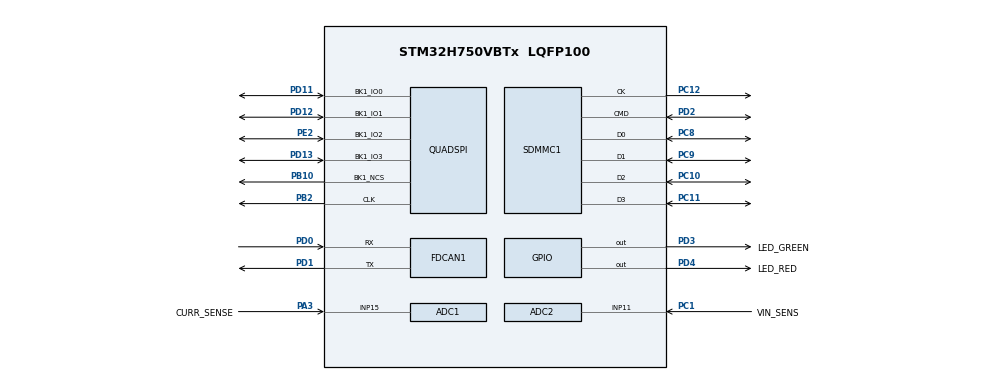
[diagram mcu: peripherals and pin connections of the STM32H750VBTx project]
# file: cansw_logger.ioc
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ADC1.Channel-0\#ChannelRegularConversion=ADC_CHANNEL_15
ADC1.ClockPrescaler=ADC_CLOCK_ASYNC_DIV64
ADC1.NbrOfConversionFlag=1
ADC1.OffsetNumber-0\#ChannelRegularConversion=ADC_OFFSET_NONE
ADC1.OffsetSignedSaturation-0\#ChannelRegularConversion=DISABLE
ADC1.Rank-0\#ChannelRegularConversion=1
ADC1.Resolution=ADC_RESOLUTION_12B
ADC1.SamplingTime-0\#ChannelRegularConversion=ADC_SAMPLETIME_1CYCLE_5
ADC1.master=1
ADC2.Channel-1\#ChannelRegularConversion=ADC_CHANNEL_11
ADC2.ClockPrescaler=ADC_CLOCK_ASYNC_DIV64
ADC2.NbrOfConversionFlag=1
ADC2.OffsetNumber-1\#ChannelRegularConversion=ADC_OFFSET_NONE
ADC2.OffsetSignedSaturation-1\#ChannelRegularConversion=DISABLE
ADC2.Rank-1\#ChannelRegularConversion=1
ADC2.Resolution=ADC_RESOLUTION_12B
ADC2.SamplingTime-1\#ChannelRegularConversion=ADC_SAMPLETIME_1CYCLE_5
CORTEX_M7.default_mode_Activation=1
FATFS.USE_DMA_CODE_SD=1
FDCAN1.CalculateBaudRateNominal=250000
FDCAN1.CalculateTimeBitNominal=4000
FDCAN1.CalculateTimeQuantumNominal=1333.3333333333333
FDCAN1.NominalPrescaler=64
FDCAN1.RxFifo0ElmtsNbr=64
FDCAN1.TxEventsNbr=32
FDCAN1.TxFifoQueueElmtsNbr=32
Mcu.Family=STM32H7
Mcu.Name=STM32H750VBTx
Mcu.Package=LQFP100
NVIC.FDCAN1_IT0_IRQn=true\:0\:0\:false\:false\:true\:true\:true\:true
NVIC.FDCAN1_IT1_IRQn=true\:0\:0\:false\:false\:true\:true\:true\:true
NVIC.FDCAN_CAL_IRQn=true\:0\:0\:false\:false\:true\:true\:true\:true
NVIC.PriorityGroup=NVIC_PRIORITYGROUP_4
NVIC.SDMMC1_IRQn=true\:0\:0\:false\:false\:true\:true\:true\:true
PA3.GPIO_Label=CURR_SENSE
PA3.Signal=ADCx_INP15
PB10.Mode=Single Bank 1
PB10.Signal=QUADSPI_BK1_NCS
PB2.Mode=Single Bank 1
PB2.Signal=QUADSPI_CLK
PC1.GPIO_Label=VIN_SENS
PC1.Signal=ADCx_INP11
PC10.Mode=SD_4_bits_Wide_bus
PC10.Signal=SDMMC1_D2
PC11.Mode=SD_4_bits_Wide_bus
PC11.Signal=SDMMC1_D3
PC12.Mode=SD_4_bits_Wide_bus
PC12.Signal=SDMMC1_CK
PC8.Mode=SD_4_bits_Wide_bus
PC8.Signal=SDMMC1_D0
PC9.Mode=SD_4_bits_Wide_bus
PC9.Signal=SDMMC1_D1
PD0.Mode=FDCAN_Activate
PD0.Signal=FDCAN1_RX
PD1.Mode=FDCAN_Activate
PD1.Signal=FDCAN1_TX
PD11.Mode=Single Bank 1
PD11.Signal=QUADSPI_BK1_IO0
PD12.Mode=Single Bank 1
PD12.Signal=QUADSPI_BK1_IO1
PD13.Mode=Single Bank 1
PD13.Signal=QUADSPI_BK1_IO3
PD2.Mode=SD_4_bits_Wide_bus
PD2.Signal=SDMMC1_CMD
PD3.GPIO_Label=LED_GREEN
PD3.Signal=GPIO_Output
PD4.GPIO_Label=LED_RED
PD4.Signal=GPIO_Output
PE2.Mode=Single Bank 1
PE2.Signal=QUADSPI_BK1_IO2
ProjectManager.HeapSize=0x200
ProjectManager.StackSize=0x400
ProjectManager.TargetToolchain=STM32CubeIDE
RCC.ADCFreq_Value=80000000
RCC.APB1Freq_Value=32000000
RCC.APB2Freq_Value=64000000
RCC.APB3Freq_Value=64000000
RCC.APB4Freq_Value=64000000
RCC.CortexFreq_Value=64000000
RCC.D2PPRE1=RCC_APB1_DIV2
RCC.DIVM1=4
RCC.DIVM2=4
RCC.DIVN1=24
RCC.DIVN2=10
RCC.DIVQ1=8
RCC.HCLKFreq_Value=64000000
RCC.PLL2FRACN=0
RCC.PLLFRACN=0
RCC.SYSCLKFreq_VALUE=64000000
RCC.USBFreq_Value=48000000
SDMMC1.ClockDiv=4
SH.ADCx_INP11.0=ADC2_INP11,IN11-Single-Ended
SH.ADCx_INP15.0=ADC1_INP15,IN15-Single-Ended
VP_FATFS_VS_SDIO.Mode=SDIO
VP_MEMORYMAP_VS_MEMORYMAP.Mode=CurAppReg
VREF+.Mode=InternalMode
VREF+.Signal=VREFBUF_OUT
board=custom

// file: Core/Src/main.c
/* USER CODE BEGIN Header */
/* USER CODE END Header */
#include "main.h"
#include "fatfs.h"

ADC_HandleTypeDef hadc1;
ADC_HandleTypeDef hadc2;

FDCAN_HandleTypeDef hfdcan1;

QSPI_HandleTypeDef hqspi;

SD_HandleTypeDef hsd1;

void SystemClock_Config(void);
void PeriphCommonClock_Config(void);
static void MPU_Config(void);
static void MX_GPIO_Init(void);
static void MX_FDCAN1_Init(void);
static void MX_ADC2_Init(void);
static void MX_SDMMC1_SD_Init(void);
static void MX_QUADSPI_Init(void);
static void MX_ADC1_Init(void);
/* USER CODE BEGIN PFP */
extern void fwmain(void);
/* USER CODE END PFP */

int main(void)
{

  /* MPU Configuration--------------------------------------------------------*/
  MPU_Config();

  /* MCU Configuration--------------------------------------------------------*/

  /* Reset of all peripherals, Initializes the Flash interface and the Systick. */
  HAL_Init();

  /* Configure the system clock */
  SystemClock_Config();

  /* Configure the peripherals common clocks */
  PeriphCommonClock_Config();

  /* Initialize all configured peripherals */
  MX_GPIO_Init();
  MX_FDCAN1_Init();
  MX_ADC2_Init();
  MX_SDMMC1_SD_Init();
  MX_QUADSPI_Init();
  MX_ADC1_Init();
  MX_FATFS_Init();
  /* USER CODE BEGIN 2 */
  fwmain();
  /* USER CODE END 2 */

  /* Infinite loop */

}

void SystemClock_Config(void)
{
  RCC_OscInitTypeDef RCC_OscInitStruct = {0};
  RCC_ClkInitTypeDef RCC_ClkInitStruct = {0};

  /** Supply configuration update enable
  */
  HAL_PWREx_ConfigSupply(PWR_LDO_SUPPLY);

  /** Configure the main internal regulator output voltage
  */
  __HAL_PWR_VOLTAGESCALING_CONFIG(PWR_REGULATOR_VOLTAGE_SCALE3);

  while(!__HAL_PWR_GET_FLAG(PWR_FLAG_VOSRDY)) {}

  /** Initializes the RCC Oscillators according to the specified parameters
  * in the RCC_OscInitTypeDef structure.
  */
  RCC_OscInitStruct.OscillatorType = RCC_OSCILLATORTYPE_HSI;
  RCC_OscInitStruct.HSIState = RCC_HSI_DIV1;
  RCC_OscInitStruct.HSICalibrationValue = RCC_HSICALIBRATION_DEFAULT;
  RCC_OscInitStruct.PLL.PLLState = RCC_PLL_ON;
  RCC_OscInitStruct.PLL.PLLSource = RCC_PLLSOURCE_HSI;
  RCC_OscInitStruct.PLL.PLLM = 4;
  RCC_OscInitStruct.PLL.PLLN = 24;
  RCC_OscInitStruct.PLL.PLLP = 2;
  RCC_OscInitStruct.PLL.PLLQ = 8;
  RCC_OscInitStruct.PLL.PLLR = 2;
  RCC_OscInitStruct.PLL.PLLRGE = RCC_PLL1VCIRANGE_3;
  RCC_OscInitStruct.PLL.PLLVCOSEL = RCC_PLL1VCOWIDE;
  RCC_OscInitStruct.PLL.PLLFRACN = 0;
  if (HAL_RCC_OscConfig(&RCC_OscInitStruct) != HAL_OK)
  {
    Error_Handler();
  }

  /** Initializes the CPU, AHB and APB buses clocks
  */
  RCC_ClkInitStruct.ClockType = RCC_CLOCKTYPE_HCLK|RCC_CLOCKTYPE_SYSCLK
                              |RCC_CLOCKTYPE_PCLK1|RCC_CLOCKTYPE_PCLK2
                              |RCC_CLOCKTYPE_D3PCLK1|RCC_CLOCKTYPE_D1PCLK1;
  RCC_ClkInitStruct.SYSCLKSource = RCC_SYSCLKSOURCE_HSI;
  RCC_ClkInitStruct.SYSCLKDivider = RCC_SYSCLK_DIV1;
  RCC_ClkInitStruct.AHBCLKDivider = RCC_HCLK_DIV1;
  RCC_ClkInitStruct.APB3CLKDivider = RCC_APB3_DIV1;
  RCC_ClkInitStruct.APB1CLKDivider = RCC_APB1_DIV2;
  RCC_ClkInitStruct.APB2CLKDivider = RCC_APB2_DIV1;
  RCC_ClkInitStruct.APB4CLKDivider = RCC_APB4_DIV1;

  if (HAL_RCC_ClockConfig(&RCC_ClkInitStruct, FLASH_LATENCY_1) != HAL_OK)
  {
    Error_Handler();
  }
}

void PeriphCommonClock_Config(void)
{
  RCC_PeriphCLKInitTypeDef PeriphClkInitStruct = {0};

  /** Initializes the peripherals clock
  */
  PeriphClkInitStruct.PeriphClockSelection = RCC_PERIPHCLK_ADC;
  PeriphClkInitStruct.PLL2.PLL2M = 4;
  PeriphClkInitStruct.PLL2.PLL2N = 10;
  PeriphClkInitStruct.PLL2.PLL2P = 2;
  PeriphClkInitStruct.PLL2.PLL2Q = 2;
  PeriphClkInitStruct.PLL2.PLL2R = 2;
  PeriphClkInitStruct.PLL2.PLL2RGE = RCC_PLL2VCIRANGE_3;
  PeriphClkInitStruct.PLL2.PLL2VCOSEL = RCC_PLL2VCOMEDIUM;
  PeriphClkInitStruct.PLL2.PLL2FRACN = 0;
  PeriphClkInitStruct.AdcClockSelection = RCC_ADCCLKSOURCE_PLL2;
  if (HAL_RCCEx_PeriphCLKConfig(&PeriphClkInitStruct) != HAL_OK)
  {
    Error_Handler();
  }
}

static void MX_ADC1_Init(void)
{

  ADC_MultiModeTypeDef multimode = {0};
  ADC_ChannelConfTypeDef sConfig = {0};

  /** Common config
  */
  hadc1.Instance = ADC1;
  hadc1.Init.ClockPrescaler = ADC_CLOCK_ASYNC_DIV64;
  hadc1.Init.Resolution = ADC_RESOLUTION_12B;
  hadc1.Init.ScanConvMode = ADC_SCAN_DISABLE;
  hadc1.Init.EOCSelection = ADC_EOC_SINGLE_CONV;
  hadc1.Init.LowPowerAutoWait = DISABLE;
  hadc1.Init.ContinuousConvMode = DISABLE;
  hadc1.Init.NbrOfConversion = 1;
  hadc1.Init.DiscontinuousConvMode = DISABLE;
  hadc1.Init.ExternalTrigConv = ADC_SOFTWARE_START;
  hadc1.Init.ExternalTrigConvEdge = ADC_EXTERNALTRIGCONVEDGE_NONE;
  hadc1.Init.ConversionDataManagement = ADC_CONVERSIONDATA_DR;
  hadc1.Init.Overrun = ADC_OVR_DATA_PRESERVED;
  hadc1.Init.LeftBitShift = ADC_LEFTBITSHIFT_NONE;
  hadc1.Init.OversamplingMode = DISABLE;
  hadc1.Init.Oversampling.Ratio = 1;
  if (HAL_ADC_Init(&hadc1) != HAL_OK)
  {
    Error_Handler();
  }

  /** Configure the ADC multi-mode
  */
  multimode.Mode = ADC_MODE_INDEPENDENT;
  if (HAL_ADCEx_MultiModeConfigChannel(&hadc1, &multimode) != HAL_OK)
  {
    Error_Handler();
  }

  /** Configure Regular Channel
  */
  sConfig.Channel = ADC_CHANNEL_15;
  sConfig.Rank = ADC_REGULAR_RANK_1;
  sConfig.SamplingTime = ADC_SAMPLETIME_1CYCLE_5;
  sConfig.SingleDiff = ADC_SINGLE_ENDED;
  sConfig.OffsetNumber = ADC_OFFSET_NONE;
  sConfig.Offset = 0;
  sConfig.OffsetSignedSaturation = DISABLE;
  if (HAL_ADC_ConfigChannel(&hadc1, &sConfig) != HAL_OK)
  {
    Error_Handler();
  }

}

static void MX_ADC2_Init(void)
{

  ADC_ChannelConfTypeDef sConfig = {0};

  /** Common config
  */
  hadc2.Instance = ADC2;
  hadc2.Init.ClockPrescaler = ADC_CLOCK_ASYNC_DIV64;
  hadc2.Init.Resolution = ADC_RESOLUTION_12B;
  hadc2.Init.ScanConvMode = ADC_SCAN_DISABLE;
  hadc2.Init.EOCSelection = ADC_EOC_SINGLE_CONV;
  hadc2.Init.LowPowerAutoWait = DISABLE;
  hadc2.Init.ContinuousConvMode = DISABLE;
  hadc2.Init.NbrOfConversion = 1;
  hadc2.Init.DiscontinuousConvMode = DISABLE;
  hadc2.Init.ExternalTrigConv = ADC_SOFTWARE_START;
  hadc2.Init.ExternalTrigConvEdge = ADC_EXTERNALTRIGCONVEDGE_NONE;
  hadc2.Init.ConversionDataManagement = ADC_CONVERSIONDATA_DR;
  hadc2.Init.Overrun = ADC_OVR_DATA_PRESERVED;
  hadc2.Init.LeftBitShift = ADC_LEFTBITSHIFT_NONE;
  hadc2.Init.OversamplingMode = DISABLE;
  hadc2.Init.Oversampling.Ratio = 1;
  if (HAL_ADC_Init(&hadc2) != HAL_OK)
  {
    Error_Handler();
  }

  /** Configure Regular Channel
  */
  sConfig.Channel = ADC_CHANNEL_11;
  sConfig.Rank = ADC_REGULAR_RANK_1;
  sConfig.SamplingTime = ADC_SAMPLETIME_1CYCLE_5;
  sConfig.SingleDiff = ADC_SINGLE_ENDED;
  sConfig.OffsetNumber = ADC_OFFSET_NONE;
  sConfig.Offset = 0;
  sConfig.OffsetSignedSaturation = DISABLE;
  if (HAL_ADC_ConfigChannel(&hadc2, &sConfig) != HAL_OK)
  {
    Error_Handler();
  }

}

static void MX_FDCAN1_Init(void)
{

  hfdcan1.Instance = FDCAN1;
  hfdcan1.Init.FrameFormat = FDCAN_FRAME_CLASSIC;
  hfdcan1.Init.Mode = FDCAN_MODE_NORMAL;
  hfdcan1.Init.AutoRetransmission = DISABLE;
  hfdcan1.Init.TransmitPause = DISABLE;
  hfdcan1.Init.ProtocolException = DISABLE;
  hfdcan1.Init.NominalPrescaler = 64;
  hfdcan1.Init.NominalSyncJumpWidth = 1;
  hfdcan1.Init.NominalTimeSeg1 = 1;
  hfdcan1.Init.NominalTimeSeg2 = 1;
  hfdcan1.Init.DataPrescaler = 1;
  hfdcan1.Init.DataSyncJumpWidth = 1;
  hfdcan1.Init.DataTimeSeg1 = 1;
  hfdcan1.Init.DataTimeSeg2 = 1;
  hfdcan1.Init.MessageRAMOffset = 0;
  hfdcan1.Init.StdFiltersNbr = 0;
  hfdcan1.Init.ExtFiltersNbr = 0;
  hfdcan1.Init.RxFifo0ElmtsNbr = 64;
  hfdcan1.Init.RxFifo0ElmtSize = FDCAN_DATA_BYTES_8;
  hfdcan1.Init.RxFifo1ElmtsNbr = 0;
  hfdcan1.Init.RxFifo1ElmtSize = FDCAN_DATA_BYTES_8;
  hfdcan1.Init.RxBuffersNbr = 0;
  hfdcan1.Init.RxBufferSize = FDCAN_DATA_BYTES_8;
  hfdcan1.Init.TxEventsNbr = 32;
  hfdcan1.Init.TxBuffersNbr = 0;
  hfdcan1.Init.TxFifoQueueElmtsNbr = 32;
  hfdcan1.Init.TxFifoQueueMode = FDCAN_TX_FIFO_OPERATION;
  hfdcan1.Init.TxElmtSize = FDCAN_DATA_BYTES_8;
  if (HAL_FDCAN_Init(&hfdcan1) != HAL_OK)
  {
    Error_Handler();
  }

}

static void MX_QUADSPI_Init(void)
{

  /* QUADSPI parameter configuration*/

  /*

  CHANGE HERE CHANGE HERE
  */
  hqspi.Instance = QUADSPI;
  hqspi.Init.ClockPrescaler = 1;
  hqspi.Init.FifoThreshold = 1;
  hqspi.Init.SampleShifting = QSPI_SAMPLE_SHIFTING_NONE;
  hqspi.Init.FlashSize = 24;
  hqspi.Init.ChipSelectHighTime = QSPI_CS_HIGH_TIME_1_CYCLE;
  hqspi.Init.ClockMode = QSPI_CLOCK_MODE_0;
  hqspi.Init.FlashID = QSPI_FLASH_ID_1;
  hqspi.Init.DualFlash = QSPI_DUALFLASH_DISABLE;
  if (HAL_QSPI_Init(&hqspi) != HAL_OK)
  {
    Error_Handler();
  }

}

static void MX_SDMMC1_SD_Init(void)
{

  hsd1.Instance = SDMMC1;
  hsd1.Init.ClockEdge = SDMMC_CLOCK_EDGE_RISING;
  hsd1.Init.ClockPowerSave = SDMMC_CLOCK_POWER_SAVE_DISABLE;
  hsd1.Init.BusWide = SDMMC_BUS_WIDE_4B;
  hsd1.Init.HardwareFlowControl = SDMMC_HARDWARE_FLOW_CONTROL_DISABLE;
  hsd1.Init.ClockDiv = 4;
  if (HAL_SD_Init(&hsd1) != HAL_OK)
  {
    Error_Handler();
  }

}

static void MX_GPIO_Init(void)
{
  GPIO_InitTypeDef GPIO_InitStruct = {0};

  /* GPIO Ports Clock Enable */
  __HAL_RCC_GPIOE_CLK_ENABLE();
  __HAL_RCC_GPIOC_CLK_ENABLE();
  __HAL_RCC_GPIOA_CLK_ENABLE();
  __HAL_RCC_GPIOB_CLK_ENABLE();
  __HAL_RCC_GPIOD_CLK_ENABLE();

  /*Configure GPIO pin Output Level */
  HAL_GPIO_WritePin(GPIOD, LED_GREEN_Pin|LED_RED_Pin, GPIO_PIN_RESET);

  /*Configure GPIO pins : LED_GREEN_Pin LED_RED_Pin */
  GPIO_InitStruct.Pin = LED_GREEN_Pin|LED_RED_Pin;
  GPIO_InitStruct.Mode = GPIO_MODE_OUTPUT_PP;
  GPIO_InitStruct.Pull = GPIO_NOPULL;
  GPIO_InitStruct.Speed = GPIO_SPEED_FREQ_LOW;
  HAL_GPIO_Init(GPIOD, &GPIO_InitStruct);

}

 /* MPU Configuration */

void MPU_Config(void)
{
  MPU_Region_InitTypeDef MPU_InitStruct = {0};

  /* Disables the MPU */
  HAL_MPU_Disable();

  /** Initializes and configures the Region and the memory to be protected
  */
  MPU_InitStruct.Enable = MPU_REGION_ENABLE;
  MPU_InitStruct.Number = MPU_REGION_NUMBER0;
  MPU_InitStruct.BaseAddress = 0x0;
  MPU_InitStruct.Size = MPU_REGION_SIZE_4GB;
  MPU_InitStruct.SubRegionDisable = 0x87;
  MPU_InitStruct.TypeExtField = MPU_TEX_LEVEL0;
  MPU_InitStruct.AccessPermission = MPU_REGION_NO_ACCESS;
  MPU_InitStruct.DisableExec = MPU_INSTRUCTION_ACCESS_DISABLE;
  MPU_InitStruct.IsShareable = MPU_ACCESS_SHAREABLE;
  MPU_InitStruct.IsCacheable = MPU_ACCESS_NOT_CACHEABLE;
  MPU_InitStruct.IsBufferable = MPU_ACCESS_NOT_BUFFERABLE;

  HAL_MPU_ConfigRegion(&MPU_InitStruct);
  /* Enables the MPU */
  HAL_MPU_Enable(MPU_PRIVILEGED_DEFAULT);

}

void Error_Handler(void)
{
}
